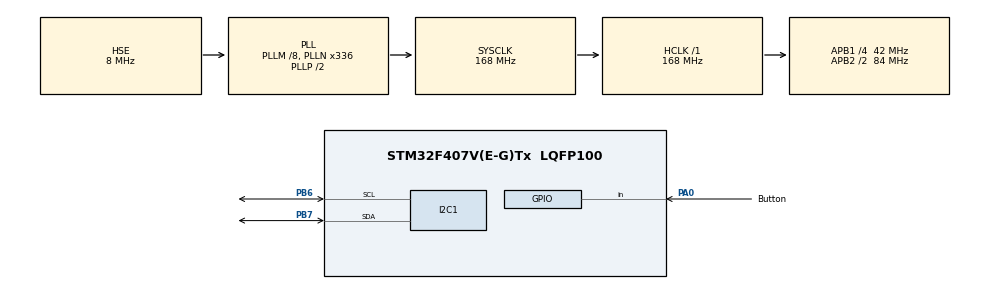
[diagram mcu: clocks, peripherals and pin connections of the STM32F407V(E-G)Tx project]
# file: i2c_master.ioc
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Mcu.Family=STM32F4
Mcu.Name=STM32F407V(E-G)Tx
Mcu.Package=LQFP100
NVIC.I2C1_ER_IRQn=true\:0\:0\:false\:false\:true\:true\:true\:true
NVIC.I2C1_EV_IRQn=true\:0\:0\:false\:false\:true\:true\:true\:true
NVIC.PriorityGroup=NVIC_PRIORITYGROUP_0
PA0-WKUP.GPIO_Label=Button
PA0-WKUP.Signal=GPIO_Input
PB6.GPIO_Pu=GPIO_PULLUP
PB6.Mode=I2C
PB6.Signal=I2C1_SCL
PB7.GPIO_Pu=GPIO_PULLUP
PB7.Mode=I2C
PB7.Signal=I2C1_SDA
PH0-OSC_IN.Mode=HSE-External-Oscillator
PH0-OSC_IN.Signal=RCC_OSC_IN
PH1-OSC_OUT.Mode=HSE-External-Oscillator
PH1-OSC_OUT.Signal=RCC_OSC_OUT
ProjectManager.HeapSize=0x200
ProjectManager.StackSize=0x400
ProjectManager.TargetToolchain=STM32CubeIDE
RCC.48MHZClocksFreq_Value=48000000
RCC.AHBFreq_Value=168000000
RCC.APB1CLKDivider=RCC_HCLK_DIV4
RCC.APB1Freq_Value=42000000
RCC.APB1TimFreq_Value=84000000
RCC.APB2CLKDivider=RCC_HCLK_DIV2
RCC.APB2Freq_Value=84000000
RCC.APB2TimFreq_Value=168000000
RCC.CortexFreq_Value=168000000
RCC.HCLKFreq_Value=168000000
RCC.HSE_VALUE=8000000
RCC.HSI_VALUE=16000000
RCC.LSE_VALUE=32768
RCC.PLLM=8
RCC.PLLN=336
RCC.PLLQ=7
RCC.PLLSourceVirtual=RCC_PLLSOURCE_HSE
RCC.SYSCLKFreq_VALUE=168000000
RCC.SYSCLKSource=RCC_SYSCLKSOURCE_PLLCLK
RCC.VCOOutputFreq_Value=336000000
board=STM32F407G-DISC1

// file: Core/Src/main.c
/* USER CODE BEGIN Header */
/**
  ******************************************************************************
  * @file           : main.c
  * @brief          : Main program body
  ******************************************************************************
  * @attention
  *
  * Copyright (c) 2023 STMicroelectronics.
  * All rights reserved.
  *
  * This software is licensed under terms that can be found in the LICENSE file
  * in the root directory of this software component.
  * If no LICENSE file comes with this software, it is provided AS-IS.
  *
  ******************************************************************************
  */
/* USER CODE END Header */
#include "main.h"
#include "i2c.h"
#include "gpio.h"

/* USER CODE BEGIN PV */
static uint8_t state=0;
static uint8_t prevState=1;
/* USER CODE END PV */

void SystemClock_Config(void);

int main(void)
{

  /* MCU Configuration--------------------------------------------------------*/

  /* Reset of all peripherals, Initializes the Flash interface and the Systick. */
  HAL_Init();

  /* Configure the system clock */
  SystemClock_Config();

  /* Initialize all configured peripherals */
  MX_GPIO_Init();
  MX_I2C1_Init();
  /* USER CODE BEGIN 2 */

  uint16_t slaveADDR = (0x12<<1);	//Slave adress "0x12" master has to shift to right by one for communication.
  uint8_t TxData1[1] = {0x1};		//LED ON
  uint8_t TxData2[1] = {0x0};		// LED OFF

  /* USER CODE END 2 */

  /* Infinite loop */
  while (1)
  {

    /* USER CODE BEGIN 3 */

	  /*///////////////////////TEXT\\\\\\\\\\\\\\\\\\\\\\\
	   *
	   * START: LED IS OFF
	   *
	   * STEP1: BUTTON HOLDING PRESSED AND LED IS ON.
	   * STEP2: BUTTON RELEASED LED STILL ON.
	   * STEP3: BUTTON HOLDING PRESSED AGAIN LED IS OFF.
	   * STEP4: BUTTON RELEASED LED STILL OFF.
	   *
	   * --------------- REWIND --------------
	   *
	   * If we use only 2 control parameter for algorithm. algorithm always ends up in if state because
	   * our first parameter is "if button is holding press or relased" another one is "state" parameter.
	   * BUTTON | STATE
	   * 	1	|	1
	   * 	1	|	0
	   * 	0	|	1
	   * 	0	| 	0
	   *
	   * That means if we hold press the button LED start to blink and we do not want that.
	   * So I also added "prevState" parameter. By adding this control parameter I can manage 8 different
	   * cases:  2^3 = 8. Thanks to that control can be achieved properly. Algorithm is given below.
	   *
	   *There is probably a much more efficient way to be found for this implementation. But I achieved
	   *There my control like this.
	   *
	   *
	   *  */

	  	  if (HAL_GPIO_ReadPin(GPIOA, GPIO_PIN_0) == GPIO_PIN_SET && state == 0)
	  	  {
	  		  if(HAL_GPIO_ReadPin(GPIOA, GPIO_PIN_0) == GPIO_PIN_SET && prevState == 1)
	  		  {
					HAL_I2C_Master_Transmit_IT(&hi2c1, slaveADDR, TxData1, 1);
					HAL_Delay(100);
					state = 1;
					prevState=1;
	  		  }
	  		  else if(HAL_GPIO_ReadPin(GPIOA, GPIO_PIN_0) == GPIO_PIN_SET && prevState == 0)
	  		  {
					HAL_I2C_Master_Transmit_IT(&hi2c1, slaveADDR, TxData2, 1);
					HAL_Delay(100);
					state=1;
					prevState=0;
	  		  }
	  	  }

	  	  else if(HAL_GPIO_ReadPin(GPIOA, GPIO_PIN_0) == GPIO_PIN_RESET && state == 1)
	  	  {
	  		  if(HAL_GPIO_ReadPin(GPIOA, GPIO_PIN_0) == GPIO_PIN_RESET && prevState == 1)
	  		  {
					HAL_I2C_Master_Transmit_IT(&hi2c1, slaveADDR, TxData1, 1);
					HAL_Delay(100);
					state=0;
					prevState=0;
	  		  }
	  		  else if(HAL_GPIO_ReadPin(GPIOA, GPIO_PIN_0) == GPIO_PIN_RESET && prevState == 0)
	  		  {
					HAL_I2C_Master_Transmit_IT(&hi2c1, slaveADDR, TxData2, 1);
					HAL_Delay(100);
					state=0;
					prevState=1;
	  		  }
	  	  }

  }
  /* USER CODE END 3 */
}

void SystemClock_Config(void)
{
  RCC_OscInitTypeDef RCC_OscInitStruct = {0};
  RCC_ClkInitTypeDef RCC_ClkInitStruct = {0};

  /** Configure the main internal regulator output voltage
  */
  __HAL_RCC_PWR_CLK_ENABLE();
  __HAL_PWR_VOLTAGESCALING_CONFIG(PWR_REGULATOR_VOLTAGE_SCALE1);

  /** Initializes the RCC Oscillators according to the specified parameters
  * in the RCC_OscInitTypeDef structure.
  */
  RCC_OscInitStruct.OscillatorType = RCC_OSCILLATORTYPE_HSE;
  RCC_OscInitStruct.HSEState = RCC_HSE_ON;
  RCC_OscInitStruct.PLL.PLLState = RCC_PLL_ON;
  RCC_OscInitStruct.PLL.PLLSource = RCC_PLLSOURCE_HSE;
  RCC_OscInitStruct.PLL.PLLM = 8;
  RCC_OscInitStruct.PLL.PLLN = 336;
  RCC_OscInitStruct.PLL.PLLP = RCC_PLLP_DIV2;
  RCC_OscInitStruct.PLL.PLLQ = 7;
  if (HAL_RCC_OscConfig(&RCC_OscInitStruct) != HAL_OK)
  {
    Error_Handler();
  }

  /** Initializes the CPU, AHB and APB buses clocks
  */
  RCC_ClkInitStruct.ClockType = RCC_CLOCKTYPE_HCLK|RCC_CLOCKTYPE_SYSCLK
                              |RCC_CLOCKTYPE_PCLK1|RCC_CLOCKTYPE_PCLK2;
  RCC_ClkInitStruct.SYSCLKSource = RCC_SYSCLKSOURCE_PLLCLK;
  RCC_ClkInitStruct.AHBCLKDivider = RCC_SYSCLK_DIV1;
  RCC_ClkInitStruct.APB1CLKDivider = RCC_HCLK_DIV4;
  RCC_ClkInitStruct.APB2CLKDivider = RCC_HCLK_DIV2;

  if (HAL_RCC_ClockConfig(&RCC_ClkInitStruct, FLASH_LATENCY_5) != HAL_OK)
  {
    Error_Handler();
  }
}

void Error_Handler(void)
{
  __disable_irq();
  while (1)
  {
  }
}
